# MDR1923VK014 register map
Vendor: Milandr; Series: ARMCM0; File version: 2.0
CPU: CM0 r0p0, little endian, no MPU, no FPU, 3 interrupt priority bits
Registers are 32-bit, read-write, reset 0x0 unless marked. A register's access mark holds for its fields unless they carry their own. Offsets are from the block's base; [hi:lo] are bit positions; {n}, {i} and the like mark numbered series.

## MDR_SSP1 — Synchronous Serial Port
Base 0x40095000
Same registers: MDR_SSP2 0x40096000, MDR_SSP3 0x40097000, MDR_SSP4 0x40098000, MDR_SSP5 0x400B1000, MDR_SSP6 0x400B2000
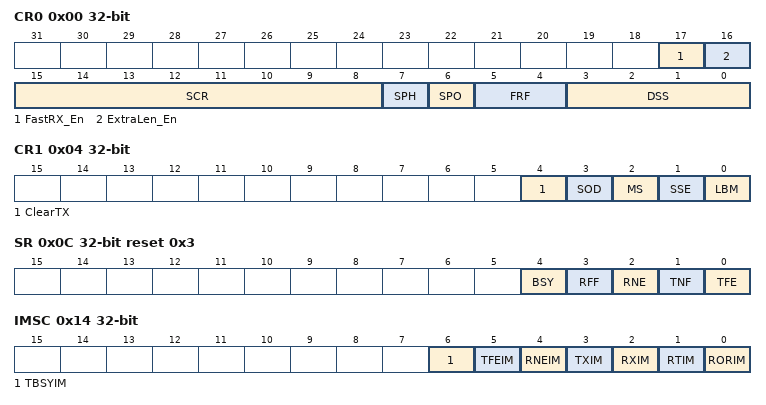
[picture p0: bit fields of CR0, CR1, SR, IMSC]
0x00 CR0 (reset mask 0xFFFF) — Control Register 0
  [17] FastRX_En — Enable fast mode for slave
    0=Off (Normal mode); 1=On (Slave in Fast mode)
  [16] ExtraLen_En — Enable extra length
    0=Off (Len by DSS); 1=On (Len by DSS + 16bit)
  [15:8] SCR — Signal CLock Rate
  [7] SPH — SPI Capture Clock Phase
    0=Leading (Capture data on leading edge); 1=Trailing (Capture data on trailing edge)
  [6] SPO — SPI Clock Polarity
    0=Idle_Low (Idle state is Low); 1=Idle_High (Idle state is High)
  [5:4] FRF — Frame Format
    0=SPI (Motorola SPI protocol); 1=SSI (Texas Instruments SSI protocol); 2=Microwire (National Semiconductor Microwire protocol)
  [3:0] DSS — Data Size Select
    {v}=bits_{v+1} (Word of {v+1} bits) (v=3..15)
0x04 CR1 (reset mask 0xF) — Control Register 1
  [4] ClearTX — Clear FIFO_TX
    0=Inactive (no action); 1=ClearFIFO
  [3] SOD — Slave mode Output Disable
    0=SlaveTxEna (Slave mode transmit enable); 1=SlaveTxDis (Slave mode transmit disable)
  [2] MS — Master or Slave mode
    0=Master Mode; 1=Slave Mode
  [1] SSE — Synchronous Serial Enable
    0=Off (SSP Disable); 1=On (SSP Enable)
  [0] LBM — Loop Back Mode
    0=Normal operation; 1=LoopBack (TX send to RX test mode)
0x08 DR — FIFO_Rx and FIFO_Tx access
  [31:0] Data — Data value
0x0C SR ro reset 0x3 — Status Register
  [4] BSY — Transfer in progress
    0=Idle (FIFO_RX is Not Full); 1=Busy (Transfering)
  [3] RFF — FIFO_RX is Full
    0=RX_NotFull (FIFO_RX is Not Full); 1=RX_Full (FIFO_RX is Full)
  [2] RNE — FIFO_RX is Not Empty
    0=RX_NotEmpty (FIFO_RX is Empty); 1=RX_Empty (FIFO_RX is Not Empty)
  [1] TNF — FIFO_TX is Not Full
    0=TX_Full (FIFO_TX is Full); 1=TX_NotFull (FIFO_TX is Not Full)
  [0] TFE — FIFO_TX is Empty
    0=TX_NotEmpty (FIFO_TX is Not Empty); 1=TX_Empty (FIFO_TX is Empty)
0x10 CPSR — Clock Prescaller Register
  [7:0] CPSDVSR — Clock Prescaller
0x14 IMSC (reset mask 0xF) — IRQ Mask Set-Clear
  [6] TBSYIM — IRQ on TX completed
    0=Off (IRQ Disable); 1=On (IRQ Enable)
  [5] TFEIM — IRQ on FIFO_TX empty
    0=Off (IRQ Disable); 1=On (IRQ Enable)
  [4] RNEIM — IRQ on FIFO_RX not empty
    0=Off (IRQ Disable); 1=On (IRQ Enable)
  [3] TXIM — Enable IQR on FIFO_TX le 4 words
    0=NoEvent (Flag Inactive); 1=TX_HalfEmpty (Flag Active)
  [2] RXIM — Enable IQR on FIFO_RX ge 4 words
    0=NoEvent (Flag Inactive); 1=RX_HalfFull (Flag Active)
  [1] RTIM — Enable IQR on RX timeout for 32bits
    0=NoEvent (Flag Inactive); 1=RX_Timeout (Flag Active)
  [0] RORIM — Enable IRQ on FIFO_RX overrun
    0=NoEvent (Flag Inactive); 1=RX_Overrun (Flag Active)
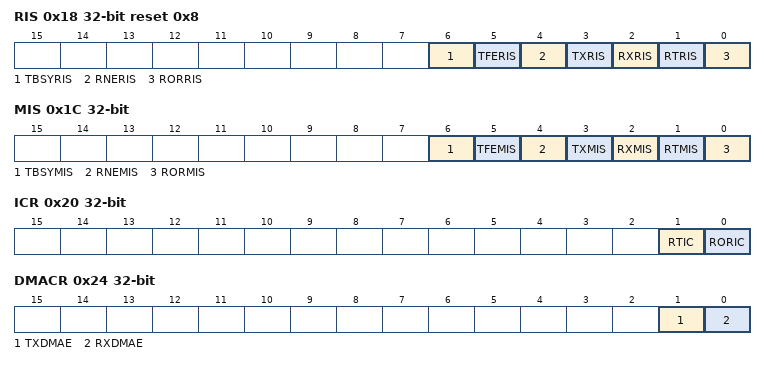
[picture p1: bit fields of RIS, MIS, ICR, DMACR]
0x18 RIS ro reset 0x8 (reset mask 0xF) — Raw Interupt Status
  [6] TBSYRIS — TX completed
    0=Off (No Event); 1=On (Event active)
  [5] TFERIS — FIFO_TX empty
    0=Off (No Event); 1=On (Event active)
  [4] RNERIS — FIFO_RX not empty
    0=Off (No Event); 1=On (Event active)
  [3] TXRIS — FIFO_TX le words
    0=NoEvent (Flag Inactive); 1=TX_HalfEmpty (Flag Active)
  [2] RXRIS — FIFO_RX gt words
    0=NoEvent (Flag Inactive); 1=RX_HalfFull (Flag Active)
  [1] RTRIS — RX timeout for 32bits
    0=NoEvent (Flag Inactive); 1=RX_Timeout (Flag Active)
  [0] RORRIS — FIFO_RX is overrun
    0=NoEvent (Flag Inactive); 1=RX_Overrun (Flag Active)
0x1C MIS ro (reset mask 0xF) — Masked Interupt Status
  [6] TBSYMIS — TX completed
    0=Off (No Event); 1=On (Event active)
  [5] TFEMIS — FIFO_TX empty
    0=Off (No Event); 1=On (Event active)
  [4] RNEMIS — FIFO_RX not empty
    0=Off (No Event); 1=On (Event active)
  [3] TXMIS — FIFO_TX le 4 words
    0=NoEvent (Flag Inactive); 1=TX_HalfEmpty (Flag Active)
  [2] RXMIS — FIFO_RX ge 4 words
    0=NoEvent (Flag Inactive); 1=RX_HalfFull (Flag Active)
  [1] RTMIS — RX timeout for 32bits
    0=NoEvent (Flag Inactive); 1=RX_Timeout (Flag Active)
  [0] RORMIS — FIFO_RX is overrun
    0=NoEvent (Flag Inactive); 1=RX_Overrun (Flag Active)
0x20 ICR wo — Interupt Clear Register
  [1] RTIC — Clear RX timeout flag
    0=Inactive (No action); 1=Clear Flag
  [0] RORIC — Clear FIFO_RX overrun flag
    0=Inactive (No action); 1=Clear Flag
0x24 DMACR — DMA Control Register
  [1] TXDMAE — Enable DMA by FIFO_TX not Full
    0=Disable DMA; 1=Enable DMA
  [0] RXDMAE — Enable DMA by FIFO_RX has data
    0=Disable DMA; 1=Enable DMA
